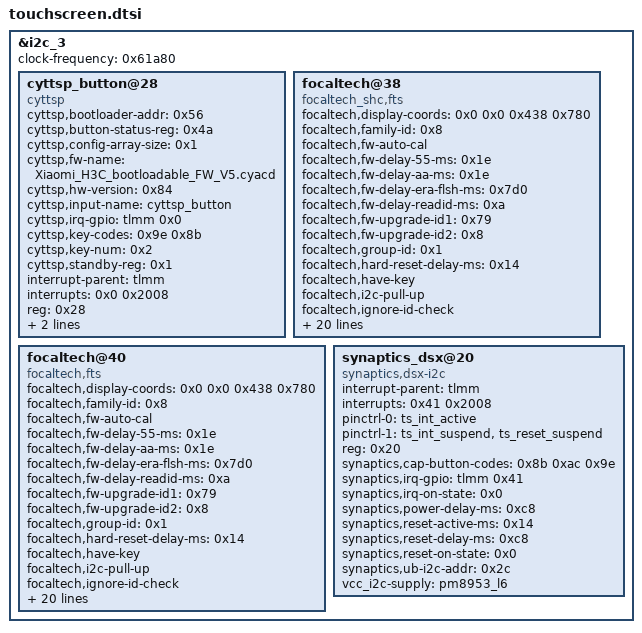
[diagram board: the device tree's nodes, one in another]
&i2c_3 {
	clock-frequency = <0x61a80>;
	status = "okay";

	cyttsp_button@28 {
		compatible = "cyttsp";
		cyttsp,bootloader-addr = <0x56>;
		cyttsp,button-status-reg = <0x4a>;
		cyttsp,config-array-size = <0x1>;
		cyttsp,fw-name = "Xiaomi_H3C_bootloadable_FW_V5.cyacd";
		cyttsp,hw-version = <0x84>;
		cyttsp,input-name = "cyttsp_button";
		cyttsp,irq-gpio = <&tlmm 0x0 0x2008>;
		cyttsp,key-codes = <0x9e 0x8b>;
		cyttsp,key-num = <0x2>;
		cyttsp,standby-reg = <0x1>;
		interrupt-parent = <&tlmm>;
		interrupts = <0x0 0x2008>;
		reg = <0x28>;
		vdd-supply = <&pm8953_l9>;
		vddio-supply = <&pm8953_l6>;
	};

	focaltech@38 {
		compatible = "focaltech_shc,fts";
		focaltech,display-coords = <0x0 0x0 0x438 0x780>;
		focaltech,family-id = <0x8>;
		focaltech,fw-auto-cal;
		focaltech,fw-delay-55-ms = <0x1e>;
		focaltech,fw-delay-aa-ms = <0x1e>;
		focaltech,fw-delay-era-flsh-ms = <0x7d0>;
		focaltech,fw-delay-readid-ms = <0xa>;
		focaltech,fw-upgrade-id1 = <0x79>;
		focaltech,fw-upgrade-id2 = <0x8>;
		focaltech,group-id = <0x1>;
		focaltech,hard-reset-delay-ms = <0x14>;
		focaltech,have-key;
		focaltech,i2c-pull-up;
		focaltech,ignore-id-check;
		focaltech,irq-gpio = <&tlmm 0x41 0x2>;
		focaltech,key-number = <0x3>;
		focaltech,key-x-coords = <0xc8 0x258 0x320>;
		focaltech,key-y-coord = <0x7d0>;
		focaltech,keys = <0x8b 0xac 0x9e>;
		focaltech,max-touch-number = <0xa>;
		focaltech,name = "fts_ts";
		focaltech,no-force-update;
		focaltech,num-max-touches = <0x5>;
		focaltech,power_ldo-gpio = <&tlmm 0x15 0x0>;
		focaltech,reset-gpio = <&tlmm 0x40 0x1>;
		focaltech,resume-in-workqueue;
		focaltech,soft-reset-delay-ms = <0xc8>;
		interrupt-parent = <&tlmm>;
		interrupts = <0x41 0x2>;
		pinctrl-0 = <&ts_int_active &ts_reset_active>;
		pinctrl-1 = <&ts_int_suspend &ts_reset_suspend>;
		pinctrl-2 = <&ts_release>;
		pinctrl-names = "pmx_ts_active", "pmx_ts_suspend", "pmx_ts_release";
		reg = <0x38>;
		vcc_i2c-supply = <&pm8953_l6>;
	};

	focaltech@40 {
		compatible = "focaltech,fts";
		focaltech,display-coords = <0x0 0x0 0x438 0x780>;
		focaltech,family-id = <0x8>;
		focaltech,fw-auto-cal;
		focaltech,fw-delay-55-ms = <0x1e>;
		focaltech,fw-delay-aa-ms = <0x1e>;
		focaltech,fw-delay-era-flsh-ms = <0x7d0>;
		focaltech,fw-delay-readid-ms = <0xa>;
		focaltech,fw-upgrade-id1 = <0x79>;
		focaltech,fw-upgrade-id2 = <0x8>;
		focaltech,group-id = <0x1>;
		focaltech,hard-reset-delay-ms = <0x14>;
		focaltech,have-key;
		focaltech,i2c-pull-up;
		focaltech,ignore-id-check;
		focaltech,irq-gpio = <&tlmm 0x41 0x2>;
		focaltech,key-number = <0x3>;
		focaltech,key-x-coords = <0x384 0xb4 0x21c>;
		focaltech,key-y-coord = <0x7f2>;
		focaltech,keys = <0x8b 0xac 0x9e>;
		focaltech,max-touch-number = <0xa>;
		focaltech,name = "fts_ts";
		focaltech,no-force-update;
		focaltech,num-max-touches = <0x5>;
		focaltech,power_ldo-gpio = <&tlmm 0x15 0x0>;
		focaltech,reset-gpio = <&tlmm 0x40 0x1>;
		focaltech,resume-in-workqueue;
		focaltech,soft-reset-delay-ms = <0xc8>;
		interrupt-parent = <&tlmm>;
		interrupts = <0x41 0x2>;
		pinctrl-0 = <&ts_int_active &ts_reset_active>;
		pinctrl-1 = <&ts_int_suspend &ts_reset_suspend>;
		pinctrl-2 = <&ts_release>;
		pinctrl-names = "pmx_ts_active", "pmx_ts_suspend", "pmx_ts_release";
		reg = <0x40>;
		vcc_i2c-supply = <&pm8953_l6>;
	};

	synaptics_dsx@20 {
		compatible = "synaptics,dsx-i2c";
		interrupt-parent = <&tlmm>;
		interrupts = <0x41 0x2008>;
		pinctrl-0 = <&ts_int_active>;
		pinctrl-1 = <&ts_int_suspend &ts_reset_suspend>;
		pinctrl-names = "pmx_ts_active", "pmx_ts_suspend";
		reg = <0x20>;
		synaptics,cap-button-codes = <0x8b 0xac 0x9e>;
		synaptics,irq-gpio = <&tlmm 0x41 0x2008>;
		synaptics,irq-on-state = <0x0>;
		synaptics,power-delay-ms = <0xc8>;
		synaptics,reset-active-ms = <0x14>;
		synaptics,reset-delay-ms = <0xc8>;
		synaptics,reset-on-state = <0x0>;
		synaptics,ub-i2c-addr = <0x2c>;
		vcc_i2c-supply = <&pm8953_l6>;
	};
};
